# STM32U083 register map
File version: 1.0
CPU: CM0+ r0p1, little endian, MPU, no FPU, 4 interrupt priority bits
Registers are 32-bit, read-write, reset 0x0 unless marked. A register's access mark holds for its fields unless they carry their own. Offsets are from the block's base; [hi:lo] are bit positions; {n}, {i} and the like mark numbered series.

## TAMP — TAMP register block
Base 0x4000B000
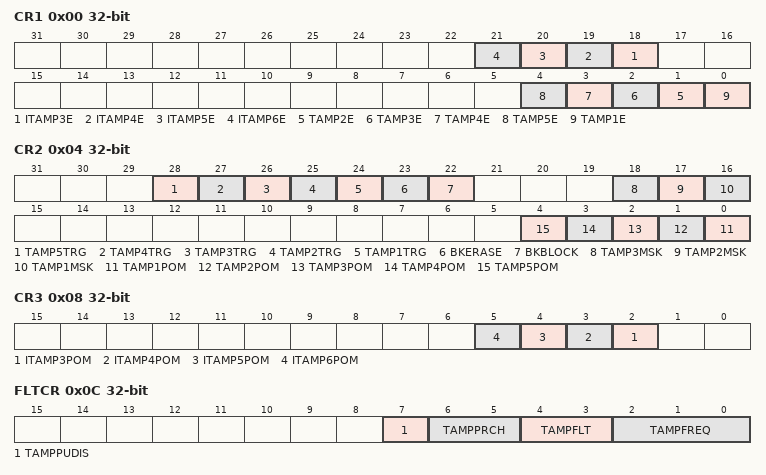
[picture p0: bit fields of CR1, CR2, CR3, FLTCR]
0x00 CR1 — TAMP control register 1
  [n+15] ITAMP{n}E (n=3..6) — Internal tamper {n} enable
  [n-1] TAMP{n}E (n=2..5) — Tamper detection on TAMP_IN{n} enable<sup>(1)</sup>
  [0] TAMP1E — Tamper detection on TAMP_IN1 enable
0x04 CR2 access per field — TAMP control register 2
  [28] TAMP5TRG rw — Active level for tamper 5 input (active mode disabled) If TAMPFLT1=100 tamper 5 input rising edge triggers a tamper detection event. If TAMPFLT1=100 tamper 5 input falling edge triggers a tamper detection event.
  [27] TAMP4TRG rw — Active level for tamper 4 input (active mode disabled) If TAMPFLT1=100 tamper 4 input rising edge triggers a tamper detection event. If TAMPFLT1=100 tamper 4 input falling edge triggers a tamper detection event.
  [26] TAMP3TRG rw — Active level for tamper 3 input If TAMPFLT1=100 tamper 3 input rising edge triggers a tamper detection event. If TAMPFLT1=100 tamper 3 input falling edge triggers a tamper detection event.
  [25] TAMP2TRG rw — Active level for tamper 2 input If TAMPFLT = 00 tamper 2 input rising edge triggers a tamper detection event. If TAMPFLT1=100 tamper 2 input falling edge triggers a tamper detection event.
  [24] TAMP1TRG rw — Active level for tamper 1 input If TAMPFLT1=100 tamper 1 input rising edge triggers a tamper detection event. If TAMPFLT1=100 tamper 1 input falling edge triggers a tamper detection event.
  [23] BKERASE wo — Backup registers and device secrets<sup>(1)</sup> erase Writing 1 to this bit reset the backup registers and device secrets<sup>(1)</sup>. Writing 0 has no effect. This bit is always read as 0.
  [22] BKBLOCK rw — Backup registers and device secrets<sup>(1)</sup> access blocked
  [18] TAMP3MSK rw — Tamper 3 mask The tamper 3 interrupt must not be enabled when TAMP3MSK is set.
  [17] TAMP2MSK rw — Tamper 2 mask The tamper 2 interrupt must not be enabled when TAMP2MSK is set.
  [16] TAMP1MSK rw — Tamper 1 mask The tamper 1 interrupt must not be enabled when TAMP1MSK is set.
  [n-1] TAMP{n}POM rw (n=1..5) — Tamper {n} potential mode
0x08 CR3 — TAMP control register 3
  [n-1] ITAMP{n}POM (n=3..6) — Internal tamper {n} potential mode
0x0C FLTCR — TAMP filter control register
  [7] TAMPPUDIS — TAMP_INx pull-up disable This bit determines if each of the TAMPx pins are precharged before each sample.
  [6:5] TAMPPRCH — TAMP_INx precharge duration These bit determines the duration of time during which the pull-up/is activated before each sample. TAMPPRCH is valid for each of the TAMP_INx inputs.
  [4:3] TAMPFLT — TAMP_INx filter count These bits determines the number of consecutive samples at the specified level (TAMP*TRG) needed to activate a tamper event. TAMPFLT is valid for each of the TAMP_INx inputs.
  [2:0] TAMPFREQ — Tamper sampling frequency Determines the frequency at which each of the TAMP_INx inputs are sampled.
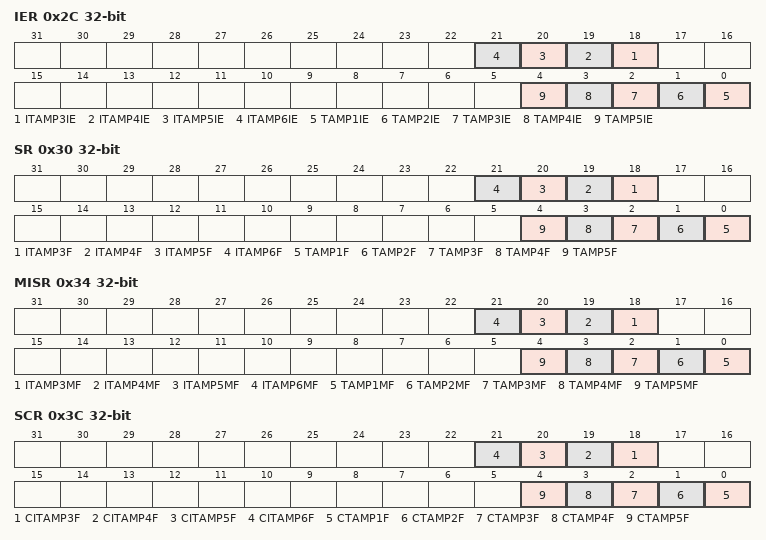
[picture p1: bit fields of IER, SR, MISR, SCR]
0x2C IER — TAMP interrupt enable register
  [n+15] ITAMP{n}IE (n=3..6) — Internal tamper {n} interrupt enable
  [n-1] TAMP{n}IE (n=1..5) — Tamper {n} interrupt enable
0x30 SR ro — TAMP status register
  [n+15] ITAMP{n}F (n=3..6) — Internal tamper {n} flag This flag is set by hardware when a tamper detection event is detected on the internal tamper {n}.
  [n-1] TAMP{n}F (n=1..5) — TAMP{n} detection flag This flag is set by hardware when a tamper detection event is detected on the TAMP{n} input.
0x34 MISR ro — TAMP masked interrupt status register
  [n+15] ITAMP{n}MF (n=3..6) — Internal tamper {n} interrupt masked flag This flag is set by hardware when the internal tamper {n} interrupt is raised.
  [n-1] TAMP{n}MF (n=1..5) — TAMP{n} interrupt masked flag This flag is set by hardware when the tamper {n} interrupt is raised.
0x3C SCR wo — TAMP status clear register
  [n+15] CITAMP{n}F (n=3..6) — Clear ITAMP{n} detection flag Writing 1 in this bit clears the ITAMP{n}F bit in the TAMP_SR register.
  [n-1] CTAMP{n}F (n=1..5) — Clear TAMP{n} detection flag Writing 1 in this bit clears the TAMP{n}F bit in the TAMP_SR register.
{0x100+4i} BKP{i}R (i=0..8) — TAMP backup {i} register
  [31:0] BKP — The application can write or read data to and from these registers. In the default (ERASE) configuration this register is reset on a tamper detection event. It is forced to reset value as long as there is at least one internal or external tamper flag being set. This register is also reset when the readout protection (RDP) is disabled.
